VERSION ""

NS_ :

BS_:

BU_: BCM

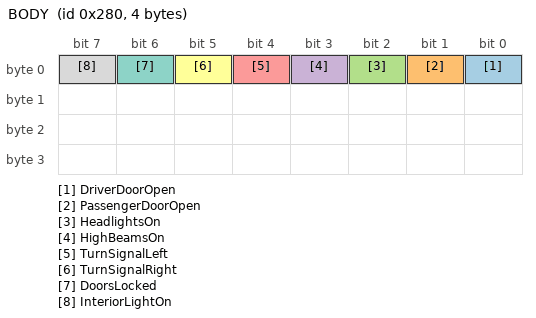
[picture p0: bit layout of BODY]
BO_ 640 BODY: 4 BCM
 SG_ DriverDoorOpen : 0|1@1+ (1,0) [0|1] "" Vector__XXX
 SG_ PassengerDoorOpen : 1|1@1+ (1,0) [0|1] "" Vector__XXX
 SG_ HeadlightsOn : 2|1@1+ (1,0) [0|1] "" Vector__XXX
 SG_ HighBeamsOn : 3|1@1+ (1,0) [0|1] "" Vector__XXX
 SG_ TurnSignalLeft : 4|1@1+ (1,0) [0|1] "" Vector__XXX
 SG_ TurnSignalRight : 5|1@1+ (1,0) [0|1] "" Vector__XXX
 SG_ DoorsLocked : 6|1@1+ (1,0) [0|1] "" Vector__XXX
 SG_ InteriorLightOn : 7|1@1+ (1,0) [0|1] "" Vector__XXX

CM_ BO_ 640 "Generic body/comfort status, a neutral reference for wiring up decode. Not vehicle-specific.";
CM_ SG_ 640 DriverDoorOpen "Driver door ajar.";
CM_ SG_ 640 HeadlightsOn "Low-beam headlights.";
CM_ SG_ 640 DoorsLocked "Central lock state.";
